# HC32F472 register map
File version: 1.0
CPU: CM4 r0p1, little endian, MPU, FPU, 4 interrupt priority bits
Registers are 32-bit, read-write, reset 0x0 unless marked. A register's access mark holds for its fields unless they carry their own. Offsets are from the block's base; [hi:lo] are bit positions; {n}, {i} and the like mark numbered series.

## CMP1 — desc CMP
Base 0x40038400
Same registers: CMP3 0x4003B000
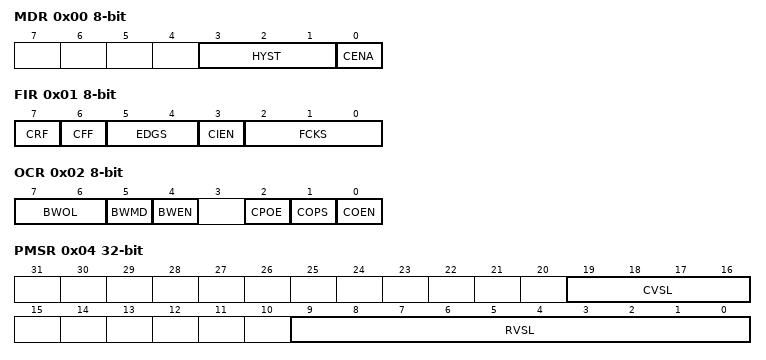
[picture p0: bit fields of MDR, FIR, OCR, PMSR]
0x00 MDR 8-bit
  [3:1] HYST, [0] CENA
0x01 FIR 8-bit
  [7] CRF, [6] CFF, [5:4] EDGS, [3] CIEN, [2:0] FCKS
0x02 OCR 8-bit
  [7:6] BWOL, [5] BWMD, [4] BWEN, [2] CPOE, [1] COPS, [0] COEN
0x03 OMR 8-bit ro
  [0] CMON
0x04 PMSR
  [19:16] CVSL, [9:0] RVSL
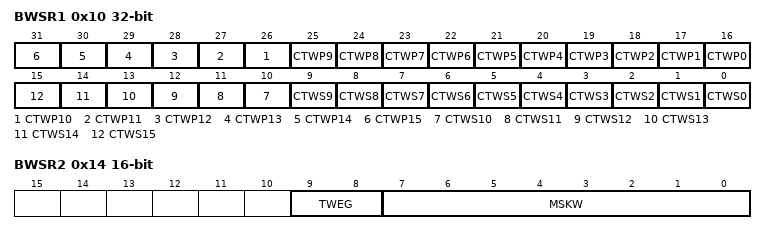
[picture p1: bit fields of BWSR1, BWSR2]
0x10 BWSR1
  [n+16] CTWP{n} (n=0..15), [n] CTWS{n} (n=0..15)
0x14 BWSR2 16-bit
  [9:8] TWEG, [7:0] MSKW

## CMP2 — desc CMP
Base 0x40038500
Same registers: CMP4 0x4003B100
Registers as CMP1; these are added or differ:
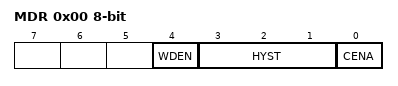
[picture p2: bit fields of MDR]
0x00 MDR 8-bit
  [4] WDEN, [3:1] HYST, [0] CENA

## CMU
Base 0x40048000
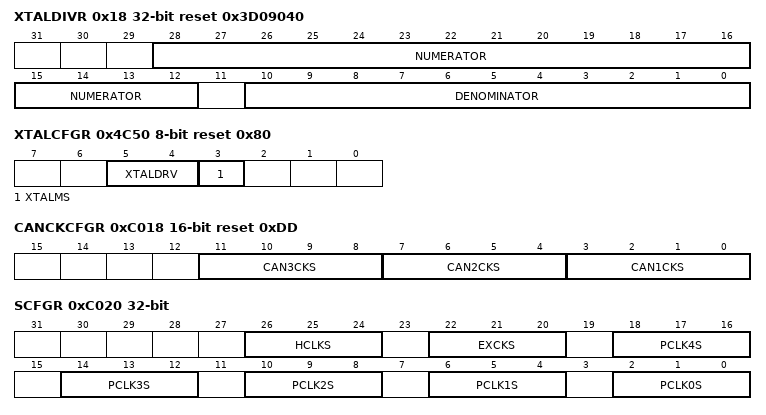
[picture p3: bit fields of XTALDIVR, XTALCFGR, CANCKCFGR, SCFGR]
0x18 XTALDIVR reset 0x3D09040
  [28:12] NUMERATOR, [10:0] DENOMINATOR
0x1C XTALDIVCR
  [0] FRADIVEN
0x4C50 XTALCFGR 8-bit reset 0x80
  [5:4] XTALDRV, [3] XTALMS
0x4C54 XTAL32CR 8-bit
  [0] XTAL32STP
0x4C58 XTAL32CFGR 8-bit
  [2:0] XTAL32DRV
0x4C68 XTAL32NFR 8-bit
  [1:0] XTAL32NF
0x4C6C LRCCR 8-bit
  [0] LRCSTP
0x4C74 LRCTRM 8-bit
0xC010 PERICKSEL 16-bit
  [3:0] PERICKSEL
0xC018 CANCKCFGR 16-bit reset 0xDD
  [11:8] CAN3CKS, [7:4] CAN2CKS, [3:0] CAN1CKS
0xC020 SCFGR
  [26:24] HCLKS, [22:20] EXCKS, [4n+2:4n] PCLK{n}S (n=0..4)
0xC024 USBCKCFGR 8-bit reset 0x40
  [7:4] USBCKS
0xC026 CKSWR 8-bit reset 0x1
  [2:0] CKSW
0xC02A PLLHCR 8-bit reset 0x1
  [0] PLLHOFF
0xC032 XTALCR 8-bit reset 0x1
  [0] XTALSTP
0xC036 HRCCR 8-bit reset 0x1
  [0] HRCSTP
0xC038 MRCCR 8-bit reset 0x80
  [0] MRCSTP
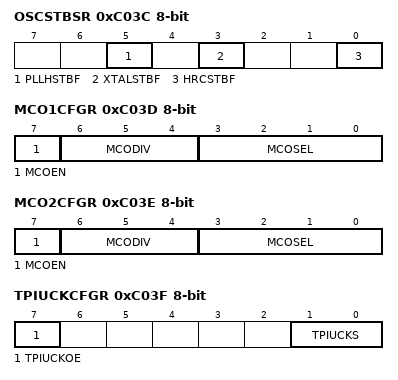
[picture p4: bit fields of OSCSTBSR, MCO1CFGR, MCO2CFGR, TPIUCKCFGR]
0xC03C OSCSTBSR 8-bit
  [5] PLLHSTBF, [3] XTALSTBF, [0] HRCSTBF
0xC03D MCO1CFGR 8-bit
  [7] MCOEN, [6:4] MCODIV, [3:0] MCOSEL
0xC03E MCO2CFGR 8-bit
  [7] MCOEN, [6:4] MCODIV, [3:0] MCOSEL
0xC03F TPIUCKCFGR 8-bit
  [7] TPIUCKOE, [1:0] TPIUCKS
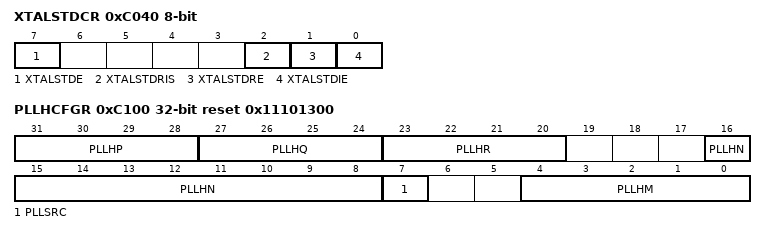
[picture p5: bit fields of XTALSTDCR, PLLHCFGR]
0xC040 XTALSTDCR 8-bit
  [7] XTALSTDE, [2] XTALSTDRIS, [1] XTALSTDRE, [0] XTALSTDIE
0xC041 XTALSTDSR 8-bit
  [0] XTALSTDF
0xC061 MRCTRM 8-bit
0xC062 HRCTRM 8-bit
0xC0A2 XTALSTBCR 8-bit reset 0x5
  [3:0] XTALSTB
0xC100 PLLHCFGR reset 0x11101300
  [31:28] PLLHP, [27:24] PLLHQ, [23:20] PLLHR, [16:8] PLLHN, [7] PLLSRC, [4:0] PLLHM

## CRC
Base 0x40008C00
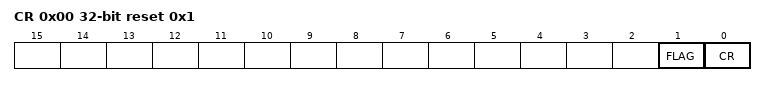
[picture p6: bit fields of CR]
0x00 CR reset 0x1
  [1] FLAG ro, [0] CR
0x04 RESLT
{0x80+4i} DAT{i} (i=0..31)

## CTC
Base 0x40049C00
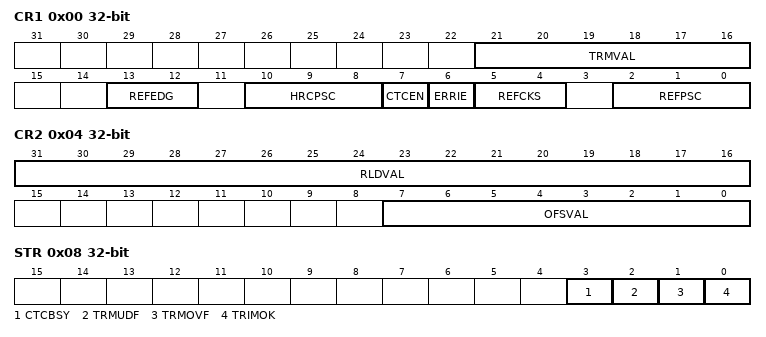
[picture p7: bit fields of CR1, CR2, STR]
0x00 CR1
  [21:16] TRMVAL, [13:12] REFEDG, [10:8] HRCPSC, [7] CTCEN, [6] ERRIE, [5:4] REFCKS, [2:0] REFPSC
0x04 CR2
  [31:16] RLDVAL, [7:0] OFSVAL
0x08 STR ro
  [3] CTCBSY, [2] TRMUDF, [1] TRMOVF, [0] TRIMOK
0x0C CNT 16-bit ro
  [15:0] CTCCNT

## DAC1 — desc DAC
Base 0x40041000
Same registers: DAC2 0x40041400, DAC3 0x40041800, DAC4 0x40041C00
0x00 DADR1 16-bit
0x02 DADR2 16-bit
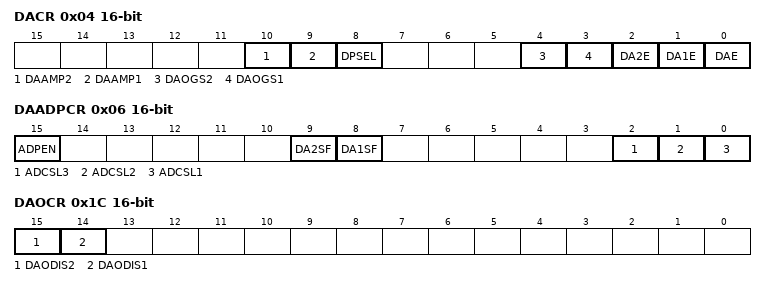
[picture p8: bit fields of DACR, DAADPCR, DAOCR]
0x04 DACR 16-bit
  [10] DAAMP2, [9] DAAMP1, [8] DPSEL, [4] DAOGS2, [3] DAOGS1, [2] DA2E, [1] DA1E, [0] DAE
0x06 DAADPCR 16-bit
  [15] ADPEN, [9] DA2SF ro, [8] DA1SF ro, [2] ADCSL3, [1] ADCSL2, [0] ADCSL1
0x1C DAOCR 16-bit
  [15] DAODIS2, [14] DAODIS1

## DBGC
Base 0xE0042000
{0x0+4i} AUTHID{i} (i=0..2)
0x0C CHIPID reset 0x48440682
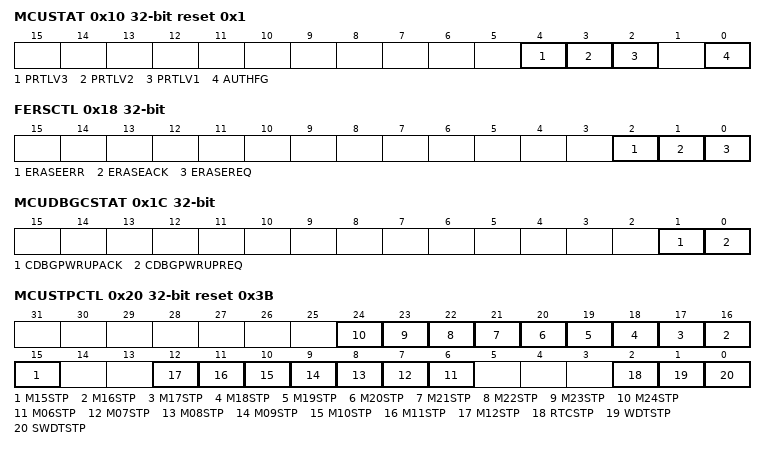
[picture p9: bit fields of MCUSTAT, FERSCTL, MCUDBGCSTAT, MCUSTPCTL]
0x10 MCUSTAT reset 0x1
  [4] PRTLV3, [3] PRTLV2, [2] PRTLV1, [0] AUTHFG
0x18 FERSCTL
  [2] ERASEERR, [1] ERASEACK, [0] ERASEREQ
0x1C MCUDBGCSTAT
  [1] CDBGPWRUPACK, [0] CDBGPWRUPREQ
0x20 MCUSTPCTL reset 0x3B
  [n] M{n}STP (n=15..24), [n] M{n:02}STP (n=6..12), [2] RTCSTP, [1] WDTSTP, [0] SWDTSTP
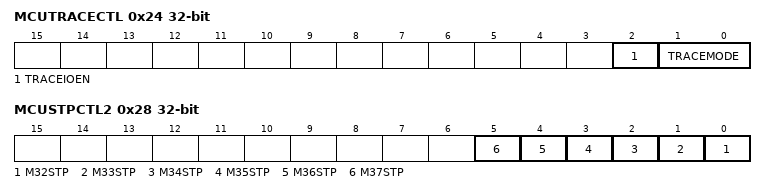
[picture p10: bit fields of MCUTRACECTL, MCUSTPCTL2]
0x24 MCUTRACECTL
  [2] TRACEIOEN, [1:0] TRACEMODE
0x28 MCUSTPCTL2
  [n-32] M{n}STP (n=32..37)

## DCU1 — desc DCU
Base 0x40056000
Same registers: DCU2 0x40056400, DCU3 0x40056800
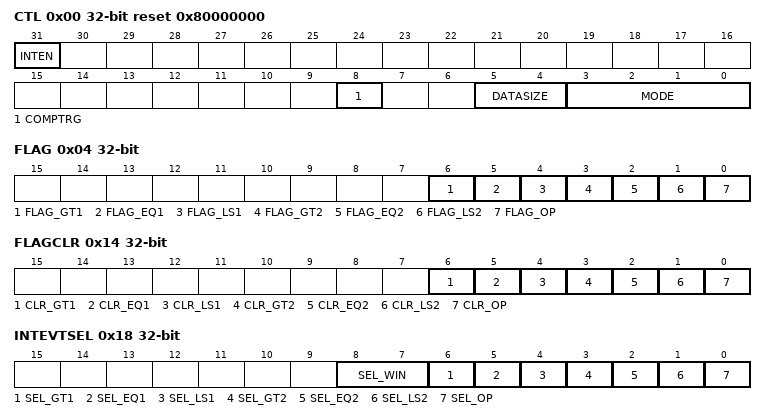
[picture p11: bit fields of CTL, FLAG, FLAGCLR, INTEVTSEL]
0x00 CTL reset 0x80000000
  [31] INTEN, [8] COMPTRG, [5:4] DATASIZE, [3:0] MODE
0x04 FLAG ro
  [6] FLAG_GT1, [5] FLAG_EQ1, [4] FLAG_LS1, [3] FLAG_GT2, [2] FLAG_EQ2, [1] FLAG_LS2, [0] FLAG_OP
{0x8+4i} DATA{i} (i=0..2)
0x14 FLAGCLR
  [6] CLR_GT1, [5] CLR_EQ1, [4] CLR_LS1, [3] CLR_GT2, [2] CLR_EQ2, [1] CLR_LS2, [0] CLR_OP
0x18 INTEVTSEL
  [8:7] SEL_WIN, [6] SEL_GT1, [5] SEL_EQ1, [4] SEL_LS1, [3] SEL_GT2, [2] SEL_EQ2, [1] SEL_LS2, [0] SEL_OP
